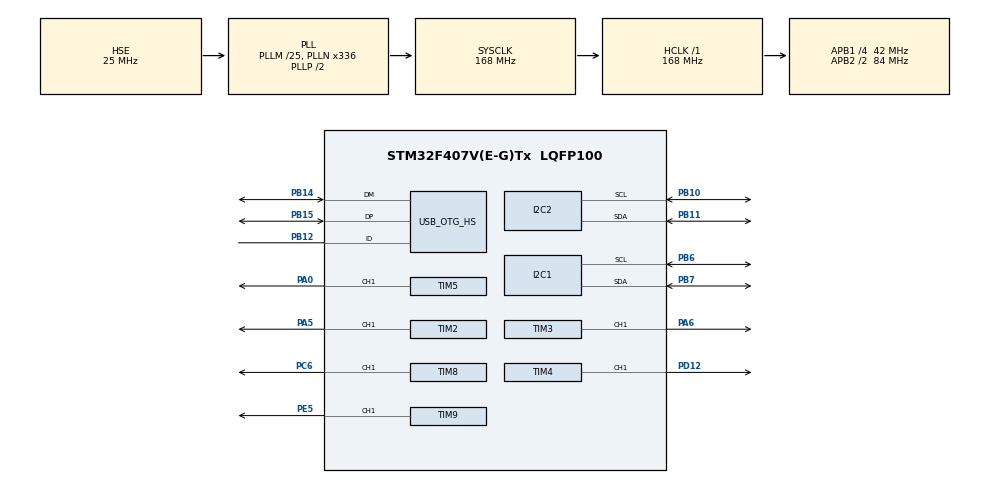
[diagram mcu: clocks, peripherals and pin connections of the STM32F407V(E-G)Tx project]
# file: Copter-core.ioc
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FREERTOS.Tasks01=defaultTask,0,128,StartDefaultTask,Default,NULL
Mcu.Family=STM32F4
Mcu.Name=STM32F407V(E-G)Tx
Mcu.Package=LQFP100
NVIC.PriorityGroup=NVIC_PRIORITYGROUP_4
NVIC.TIM1_UP_TIM10_IRQn=true\:0\:0\:false\:false\:true\:false\:false
NVIC.TimeBase=TIM1_UP_TIM10_IRQn
NVIC.TimeBaseIP=TIM1
PA0-WKUP.Signal=S_TIM5_CH1
PA13.Mode=JTAG_4_pins
PA13.Signal=SYS_JTMS-SWDIO
PA14.Mode=JTAG_4_pins
PA14.Signal=SYS_JTCK-SWCLK
PA15.Mode=JTAG_4_pins
PA15.Signal=SYS_JTDI
PA5.Signal=S_TIM2_CH1_ETR
PA6.Signal=S_TIM3_CH1
PB10.Mode=I2C
PB10.Signal=I2C2_SCL
PB11.Mode=I2C
PB11.Signal=I2C2_SDA
PB12.Mode=OTG/Dual-Role-Device-FS
PB12.Signal=USB_OTG_HS_ID
PB14.Mode=OTG/Dual-Role-Device-FS
PB14.Signal=USB_OTG_HS_DM
PB15.Mode=OTG/Dual-Role-Device-FS
PB15.Signal=USB_OTG_HS_DP
PB3.Mode=JTAG_4_pins
PB3.Signal=SYS_JTDO-SWO
PB6.Mode=I2C
PB6.Signal=I2C1_SCL
PB7.Mode=I2C
PB7.Signal=I2C1_SDA
PC6.Signal=S_TIM8_CH1
PD12.Signal=S_TIM4_CH1
PE5.Signal=S_TIM9_CH1
PH0-OSC_IN.Mode=HSE-External-Oscillator
PH0-OSC_IN.Signal=RCC_OSC_IN
PH1-OSC_OUT.Mode=HSE-External-Oscillator
PH1-OSC_OUT.Signal=RCC_OSC_OUT
ProjectManager.HeapSize=0x200
ProjectManager.StackSize=0x400
ProjectManager.TargetToolchain=TrueSTUDIO
RCC.48MHZClocksFreq_Value=48000000
RCC.AHBFreq_Value=168000000
RCC.APB1CLKDivider=RCC_HCLK_DIV4
RCC.APB1Freq_Value=42000000
RCC.APB1TimFreq_Value=84000000
RCC.APB2CLKDivider=RCC_HCLK_DIV2
RCC.APB2Freq_Value=84000000
RCC.APB2TimFreq_Value=168000000
RCC.CortexFreq_Value=168000000
RCC.HCLKFreq_Value=168000000
RCC.HSE_VALUE=25000000
RCC.HSI_VALUE=16000000
RCC.LSE_VALUE=32768
RCC.PLLM=25
RCC.PLLN=336
RCC.PLLQ=7
RCC.SYSCLKFreq_VALUE=168000000
RCC.SYSCLKSource=RCC_SYSCLKSOURCE_PLLCLK
RCC.VCOOutputFreq_Value=336000000
SH.S_TIM2_CH1_ETR.0=TIM2_CH1,PWM Generation1 CH1
SH.S_TIM3_CH1.0=TIM3_CH1,PWM Generation1 CH1
SH.S_TIM4_CH1.0=TIM4_CH1,PWM Generation1 CH1
SH.S_TIM5_CH1.0=TIM5_CH1,PWM Generation1 CH1
SH.S_TIM8_CH1.0=TIM8_CH1,PWM Generation1 CH1
SH.S_TIM9_CH1.0=TIM9_CH1,PWM Generation1 CH1
TIM2.Channel-PWM\ Generation1\ CH1=TIM_CHANNEL_1
TIM3.Channel-PWM\ Generation1\ CH1=TIM_CHANNEL_1
TIM4.Channel-PWM\ Generation1\ CH1=TIM_CHANNEL_1
TIM5.Channel-PWM\ Generation1\ CH1=TIM_CHANNEL_1
TIM8.Channel-PWM\ Generation1\ CH1=TIM_CHANNEL_1
TIM9.Channel-PWM\ Generation1\ CH1=TIM_CHANNEL_1
VP_FREERTOS_VS_ENABLE.Mode=Enabled
VP_SYS_VS_tim1.Mode=TIM1
board=Copter-core

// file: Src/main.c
/**
  ******************************************************************************
  * File Name          : main.c
  * Description        : Main program body
  ******************************************************************************
  * This notice applies to any and all portions of this file
  * that are not between comment pairs USER CODE BEGIN and
  * USER CODE END. Other portions of this file, whether
  * inserted by the user or by software development tools
  * are owned by their respective copyright owners.
  *
  * Copyright (c) 2018 STMicroelectronics International N.V.
  * All rights reserved.
  *
  * Redistribution and use in source and binary forms, with or without
  * modification, are permitted, provided that the following conditions are met:
  *
  * 1. Redistribution of source code must retain the above copyright notice,
  *    this list of conditions and the following disclaimer.
  * 2. Redistributions in binary form must reproduce the above copyright notice,
  *    this list of conditions and the following disclaimer in the documentation
  *    and/or other materials provided with the distribution.
  * 3. Neither the name of STMicroelectronics nor the names of other
  *    contributors to this software may be used to endorse or promote products
  *    derived from this software without specific written permission.
  * 4. This software, including modifications and/or derivative works of this
  *    software, must execute solely and exclusively on microcontroller or
  *    microprocessor devices manufactured by or for STMicroelectronics.
  * 5. Redistribution and use of this software other than as permitted under
  *    this license is void and will automatically terminate your rights under
  *    this license.
  *
  * THIS SOFTWARE IS PROVIDED BY STMICROELECTRONICS AND CONTRIBUTORS "AS IS"
  * AND ANY EXPRESS, IMPLIED OR STATUTORY WARRANTIES, INCLUDING, BUT NOT
  * LIMITED TO, THE IMPLIED WARRANTIES OF MERCHANTABILITY, FITNESS FOR A
  * PARTICULAR PURPOSE AND NON-INFRINGEMENT OF THIRD PARTY INTELLECTUAL PROPERTY
  * RIGHTS ARE DISCLAIMED TO THE FULLEST EXTENT PERMITTED BY LAW. IN NO EVENT
  * SHALL STMICROELECTRONICS OR CONTRIBUTORS BE LIABLE FOR ANY DIRECT, INDIRECT,
  * INCIDENTAL, SPECIAL, EXEMPLARY, OR CONSEQUENTIAL DAMAGES (INCLUDING, BUT NOT
  * LIMITED TO, PROCUREMENT OF SUBSTITUTE GOODS OR SERVICES; LOSS OF USE, DATA,
  * OR PROFITS; OR BUSINESS INTERRUPTION) HOWEVER CAUSED AND ON ANY THEORY OF
  * LIABILITY, WHETHER IN CONTRACT, STRICT LIABILITY, OR TORT (INCLUDING
  * NEGLIGENCE OR OTHERWISE) ARISING IN ANY WAY OUT OF THE USE OF THIS SOFTWARE,
  * EVEN IF ADVISED OF THE POSSIBILITY OF SUCH DAMAGE.
  *
  ******************************************************************************
  */
#include "main.h"
#include "stm32f4xx_hal.h"
#include "cmsis_os.h"

/* USER CODE BEGIN Includes */
#include "barometer.h"
#include "orientation.h"

/* USER CODE END Includes */

I2C_HandleTypeDef hi2c1;
I2C_HandleTypeDef hi2c2;

TIM_HandleTypeDef htim2;
TIM_HandleTypeDef htim3;
TIM_HandleTypeDef htim4;
TIM_HandleTypeDef htim5;
TIM_HandleTypeDef htim8;
TIM_HandleTypeDef htim9;

osThreadId defaultTaskHandle;

/* USER CODE BEGIN PV */
/* Private variables ---------------------------------------------------------*/

/* Task Priority Definitions */
#define TASK_INIT_PRIO	(configMAX_PRIORITIES - 1)
#define TASK_MAIN_PRIO	(tskIDLE_PRIORITY + 1)

/* Task Stack Definitions */
#define DEFAULT_STACK_SIZE	256

/* USER CODE END PV */

void SystemClock_Config(void);
static void MX_GPIO_Init(void);
static void MX_TIM4_Init(void);
static void MX_TIM3_Init(void);
static void MX_TIM2_Init(void);
static void MX_TIM5_Init(void);
static void MX_TIM8_Init(void);
static void MX_TIM9_Init(void);
static void MX_USB_OTG_HS_USB_Init(void);
static void MX_I2C2_Init(void);
static void MX_I2C1_Init(void);
void StartDefaultTask(void const * argument);

void HAL_TIM_MspPostInit(TIM_HandleTypeDef *htim);

/* USER CODE BEGIN PFP */
/* Private function prototypes -----------------------------------------------*/

/* USER CODE END PFP */

int main(void)
{

  /* MCU Configuration----------------------------------------------------------*/

  /* Reset of all peripherals, Initializes the Flash interface and the Systick. */
  HAL_Init();

  /* Configure the system clock */
  SystemClock_Config();

  /* Initialize all configured peripherals */
  MX_GPIO_Init();
  MX_TIM4_Init();
  MX_TIM3_Init();
  MX_TIM2_Init();
  MX_TIM5_Init();
  MX_TIM8_Init();
  MX_TIM9_Init();
  MX_USB_OTG_HS_USB_Init();
  MX_I2C2_Init();
  MX_I2C1_Init();

  /* Create the thread(s) */
  /* definition and creation of defaultTask */
  osThreadDef(defaultTask, StartDefaultTask, osPriorityNormal, 0, 128);
  defaultTaskHandle = osThreadCreate(osThread(defaultTask), NULL);

  /* USER CODE BEGIN RTOS_THREADS */
  /* add threads, ... */
  xTaskCreate(Task_Orientation, "MAIN_ORIENTATION", DEFAULT_STACK_SIZE, NULL, TASK_MAIN_PRIO, NULL);
  xTaskCreate(Task_Barometer, "MAIN_BAROMETER", DEFAULT_STACK_SIZE, NULL, TASK_MAIN_PRIO, NULL);
  //xTaskCreate(Task_USB, "MAIN_USB", DEFAULT_STACK_SIZE, NULL, TASK_MAIN_PRIO, NULL);
  /* USER CODE END RTOS_THREADS */

  /* Start scheduler */
  osKernelStart();

  /* We should never get here as control is now taken by the scheduler */

  /* Infinite loop */
  while (1)
  {

  }

}

/** System Clock Configuration
*/
void SystemClock_Config(void)
{

  RCC_OscInitTypeDef RCC_OscInitStruct;
  RCC_ClkInitTypeDef RCC_ClkInitStruct;

    /**Configure the main internal regulator output voltage
    */
  __HAL_RCC_PWR_CLK_ENABLE();

  __HAL_PWR_VOLTAGESCALING_CONFIG(PWR_REGULATOR_VOLTAGE_SCALE1);

    /**Initializes the CPU, AHB and APB busses clocks
    */
  RCC_OscInitStruct.OscillatorType = RCC_OSCILLATORTYPE_HSE;
  RCC_OscInitStruct.HSEState = RCC_HSE_ON;
  RCC_OscInitStruct.PLL.PLLState = RCC_PLL_ON;
  RCC_OscInitStruct.PLL.PLLSource = RCC_PLLSOURCE_HSE;
  RCC_OscInitStruct.PLL.PLLM = 25;
  RCC_OscInitStruct.PLL.PLLN = 336;
  RCC_OscInitStruct.PLL.PLLP = RCC_PLLP_DIV2;
  RCC_OscInitStruct.PLL.PLLQ = 7;
  if (HAL_RCC_OscConfig(&RCC_OscInitStruct) != HAL_OK)
  {
    _Error_Handler(__FILE__, __LINE__);
  }

    /**Initializes the CPU, AHB and APB busses clocks
    */
  RCC_ClkInitStruct.ClockType = RCC_CLOCKTYPE_HCLK|RCC_CLOCKTYPE_SYSCLK
                              |RCC_CLOCKTYPE_PCLK1|RCC_CLOCKTYPE_PCLK2;
  RCC_ClkInitStruct.SYSCLKSource = RCC_SYSCLKSOURCE_PLLCLK;
  RCC_ClkInitStruct.AHBCLKDivider = RCC_SYSCLK_DIV1;
  RCC_ClkInitStruct.APB1CLKDivider = RCC_HCLK_DIV4;
  RCC_ClkInitStruct.APB2CLKDivider = RCC_HCLK_DIV2;

  if (HAL_RCC_ClockConfig(&RCC_ClkInitStruct, FLASH_LATENCY_5) != HAL_OK)
  {
    _Error_Handler(__FILE__, __LINE__);
  }

    /**Configure the Systick interrupt time
    */
  HAL_SYSTICK_Config(HAL_RCC_GetHCLKFreq()/1000);

    /**Configure the Systick
    */
  HAL_SYSTICK_CLKSourceConfig(SYSTICK_CLKSOURCE_HCLK);

  /* SysTick_IRQn interrupt configuration */
  HAL_NVIC_SetPriority(SysTick_IRQn, 15, 0);
}

/* I2C1 init function */
static void MX_I2C1_Init(void)
{

  hi2c1.Instance = I2C1;
  hi2c1.Init.ClockSpeed = 100000;
  hi2c1.Init.DutyCycle = I2C_DUTYCYCLE_2;
  hi2c1.Init.OwnAddress1 = 0;
  hi2c1.Init.AddressingMode = I2C_ADDRESSINGMODE_7BIT;
  hi2c1.Init.DualAddressMode = I2C_DUALADDRESS_DISABLE;
  hi2c1.Init.OwnAddress2 = 0;
  hi2c1.Init.GeneralCallMode = I2C_GENERALCALL_DISABLE;
  hi2c1.Init.NoStretchMode = I2C_NOSTRETCH_DISABLE;
  if (HAL_I2C_Init(&hi2c1) != HAL_OK)
  {
    _Error_Handler(__FILE__, __LINE__);
  }

}

/* I2C2 init function */
static void MX_I2C2_Init(void)
{

  hi2c2.Instance = I2C2;
  hi2c2.Init.ClockSpeed = 100000;
  hi2c2.Init.DutyCycle = I2C_DUTYCYCLE_2;
  hi2c2.Init.OwnAddress1 = 0;
  hi2c2.Init.AddressingMode = I2C_ADDRESSINGMODE_7BIT;
  hi2c2.Init.DualAddressMode = I2C_DUALADDRESS_DISABLE;
  hi2c2.Init.OwnAddress2 = 0;
  hi2c2.Init.GeneralCallMode = I2C_GENERALCALL_DISABLE;
  hi2c2.Init.NoStretchMode = I2C_NOSTRETCH_DISABLE;
  if (HAL_I2C_Init(&hi2c2) != HAL_OK)
  {
    _Error_Handler(__FILE__, __LINE__);
  }

}

/* TIM2 init function */
static void MX_TIM2_Init(void)
{

  TIM_MasterConfigTypeDef sMasterConfig;
  TIM_OC_InitTypeDef sConfigOC;

  htim2.Instance = TIM2;
  htim2.Init.Prescaler = 0;
  htim2.Init.CounterMode = TIM_COUNTERMODE_UP;
  htim2.Init.Period = 0;
  htim2.Init.ClockDivision = TIM_CLOCKDIVISION_DIV1;
  if (HAL_TIM_PWM_Init(&htim2) != HAL_OK)
  {
    _Error_Handler(__FILE__, __LINE__);
  }

  sMasterConfig.MasterOutputTrigger = TIM_TRGO_RESET;
  sMasterConfig.MasterSlaveMode = TIM_MASTERSLAVEMODE_DISABLE;
  if (HAL_TIMEx_MasterConfigSynchronization(&htim2, &sMasterConfig) != HAL_OK)
  {
    _Error_Handler(__FILE__, __LINE__);
  }

  sConfigOC.OCMode = TIM_OCMODE_PWM1;
  sConfigOC.Pulse = 0;
  sConfigOC.OCPolarity = TIM_OCPOLARITY_HIGH;
  sConfigOC.OCFastMode = TIM_OCFAST_DISABLE;
  if (HAL_TIM_PWM_ConfigChannel(&htim2, &sConfigOC, TIM_CHANNEL_1) != HAL_OK)
  {
    _Error_Handler(__FILE__, __LINE__);
  }

  HAL_TIM_MspPostInit(&htim2);

}

/* TIM3 init function */
static void MX_TIM3_Init(void)
{

  TIM_MasterConfigTypeDef sMasterConfig;
  TIM_OC_InitTypeDef sConfigOC;

  htim3.Instance = TIM3;
  htim3.Init.Prescaler = 0;
  htim3.Init.CounterMode = TIM_COUNTERMODE_UP;
  htim3.Init.Period = 0;
  htim3.Init.ClockDivision = TIM_CLOCKDIVISION_DIV1;
  if (HAL_TIM_PWM_Init(&htim3) != HAL_OK)
  {
    _Error_Handler(__FILE__, __LINE__);
  }

  sMasterConfig.MasterOutputTrigger = TIM_TRGO_RESET;
  sMasterConfig.MasterSlaveMode = TIM_MASTERSLAVEMODE_DISABLE;
  if (HAL_TIMEx_MasterConfigSynchronization(&htim3, &sMasterConfig) != HAL_OK)
  {
    _Error_Handler(__FILE__, __LINE__);
  }

  sConfigOC.OCMode = TIM_OCMODE_PWM1;
  sConfigOC.Pulse = 0;
  sConfigOC.OCPolarity = TIM_OCPOLARITY_HIGH;
  sConfigOC.OCFastMode = TIM_OCFAST_DISABLE;
  if (HAL_TIM_PWM_ConfigChannel(&htim3, &sConfigOC, TIM_CHANNEL_1) != HAL_OK)
  {
    _Error_Handler(__FILE__, __LINE__);
  }

  HAL_TIM_MspPostInit(&htim3);

}

/* TIM4 init function */
static void MX_TIM4_Init(void)
{

  TIM_MasterConfigTypeDef sMasterConfig;
  TIM_OC_InitTypeDef sConfigOC;

  htim4.Instance = TIM4;
  htim4.Init.Prescaler = 0;
  htim4.Init.CounterMode = TIM_COUNTERMODE_UP;
  htim4.Init.Period = 0;
  htim4.Init.ClockDivision = TIM_CLOCKDIVISION_DIV1;
  if (HAL_TIM_PWM_Init(&htim4) != HAL_OK)
  {
    _Error_Handler(__FILE__, __LINE__);
  }

  sMasterConfig.MasterOutputTrigger = TIM_TRGO_RESET;
  sMasterConfig.MasterSlaveMode = TIM_MASTERSLAVEMODE_DISABLE;
  if (HAL_TIMEx_MasterConfigSynchronization(&htim4, &sMasterConfig) != HAL_OK)
  {
    _Error_Handler(__FILE__, __LINE__);
  }

  sConfigOC.OCMode = TIM_OCMODE_PWM1;
  sConfigOC.Pulse = 0;
  sConfigOC.OCPolarity = TIM_OCPOLARITY_HIGH;
  sConfigOC.OCFastMode = TIM_OCFAST_DISABLE;
  if (HAL_TIM_PWM_ConfigChannel(&htim4, &sConfigOC, TIM_CHANNEL_1) != HAL_OK)
  {
    _Error_Handler(__FILE__, __LINE__);
  }

  HAL_TIM_MspPostInit(&htim4);

}

/* TIM5 init function */
static void MX_TIM5_Init(void)
{

  TIM_MasterConfigTypeDef sMasterConfig;
  TIM_OC_InitTypeDef sConfigOC;

  htim5.Instance = TIM5;
  htim5.Init.Prescaler = 0;
  htim5.Init.CounterMode = TIM_COUNTERMODE_UP;
  htim5.Init.Period = 0;
  htim5.Init.ClockDivision = TIM_CLOCKDIVISION_DIV1;
  if (HAL_TIM_PWM_Init(&htim5) != HAL_OK)
  {
    _Error_Handler(__FILE__, __LINE__);
  }

  sMasterConfig.MasterOutputTrigger = TIM_TRGO_RESET;
  sMasterConfig.MasterSlaveMode = TIM_MASTERSLAVEMODE_DISABLE;
  if (HAL_TIMEx_MasterConfigSynchronization(&htim5, &sMasterConfig) != HAL_OK)
  {
    _Error_Handler(__FILE__, __LINE__);
  }

  sConfigOC.OCMode = TIM_OCMODE_PWM1;
  sConfigOC.Pulse = 0;
  sConfigOC.OCPolarity = TIM_OCPOLARITY_HIGH;
  sConfigOC.OCFastMode = TIM_OCFAST_DISABLE;
  if (HAL_TIM_PWM_ConfigChannel(&htim5, &sConfigOC, TIM_CHANNEL_1) != HAL_OK)
  {
    _Error_Handler(__FILE__, __LINE__);
  }

  HAL_TIM_MspPostInit(&htim5);

}

/* TIM8 init function */
static void MX_TIM8_Init(void)
{

  TIM_MasterConfigTypeDef sMasterConfig;
  TIM_OC_InitTypeDef sConfigOC;
  TIM_BreakDeadTimeConfigTypeDef sBreakDeadTimeConfig;

  htim8.Instance = TIM8;
  htim8.Init.Prescaler = 0;
  htim8.Init.CounterMode = TIM_COUNTERMODE_UP;
  htim8.Init.Period = 0;
  htim8.Init.ClockDivision = TIM_CLOCKDIVISION_DIV1;
  htim8.Init.RepetitionCounter = 0;
  if (HAL_TIM_PWM_Init(&htim8) != HAL_OK)
  {
    _Error_Handler(__FILE__, __LINE__);
  }

  sMasterConfig.MasterOutputTrigger = TIM_TRGO_RESET;
  sMasterConfig.MasterSlaveMode = TIM_MASTERSLAVEMODE_DISABLE;
  if (HAL_TIMEx_MasterConfigSynchronization(&htim8, &sMasterConfig) != HAL_OK)
  {
    _Error_Handler(__FILE__, __LINE__);
  }

  sConfigOC.OCMode = TIM_OCMODE_PWM1;
  sConfigOC.Pulse = 0;
  sConfigOC.OCPolarity = TIM_OCPOLARITY_HIGH;
  sConfigOC.OCNPolarity = TIM_OCNPOLARITY_HIGH;
  sConfigOC.OCFastMode = TIM_OCFAST_DISABLE;
  sConfigOC.OCIdleState = TIM_OCIDLESTATE_RESET;
  sConfigOC.OCNIdleState = TIM_OCNIDLESTATE_RESET;
  if (HAL_TIM_PWM_ConfigChannel(&htim8, &sConfigOC, TIM_CHANNEL_1) != HAL_OK)
  {
    _Error_Handler(__FILE__, __LINE__);
  }

  sBreakDeadTimeConfig.OffStateRunMode = TIM_OSSR_DISABLE;
  sBreakDeadTimeConfig.OffStateIDLEMode = TIM_OSSI_DISABLE;
  sBreakDeadTimeConfig.LockLevel = TIM_LOCKLEVEL_OFF;
  sBreakDeadTimeConfig.DeadTime = 0;
  sBreakDeadTimeConfig.BreakState = TIM_BREAK_DISABLE;
  sBreakDeadTimeConfig.BreakPolarity = TIM_BREAKPOLARITY_HIGH;
  sBreakDeadTimeConfig.AutomaticOutput = TIM_AUTOMATICOUTPUT_DISABLE;
  if (HAL_TIMEx_ConfigBreakDeadTime(&htim8, &sBreakDeadTimeConfig) != HAL_OK)
  {
    _Error_Handler(__FILE__, __LINE__);
  }

  HAL_TIM_MspPostInit(&htim8);

}

/* TIM9 init function */
static void MX_TIM9_Init(void)
{

  TIM_OC_InitTypeDef sConfigOC;

  htim9.Instance = TIM9;
  htim9.Init.Prescaler = 0;
  htim9.Init.CounterMode = TIM_COUNTERMODE_UP;
  htim9.Init.Period = 0;
  htim9.Init.ClockDivision = TIM_CLOCKDIVISION_DIV1;
  if (HAL_TIM_PWM_Init(&htim9) != HAL_OK)
  {
    _Error_Handler(__FILE__, __LINE__);
  }

  sConfigOC.OCMode = TIM_OCMODE_PWM1;
  sConfigOC.Pulse = 0;
  sConfigOC.OCPolarity = TIM_OCPOLARITY_HIGH;
  sConfigOC.OCFastMode = TIM_OCFAST_DISABLE;
  if (HAL_TIM_PWM_ConfigChannel(&htim9, &sConfigOC, TIM_CHANNEL_1) != HAL_OK)
  {
    _Error_Handler(__FILE__, __LINE__);
  }

  HAL_TIM_MspPostInit(&htim9);

}

/* USB_OTG_HS init function */
static void MX_USB_OTG_HS_USB_Init(void)
{

}

/** Configure pins as
        * Analog
        * Input
        * Output
        * EVENT_OUT
        * EXTI
     PB12   ------> USB_OTG_HS_ID
     PB14   ------> USB_OTG_HS_DM
     PB15   ------> USB_OTG_HS_DP
*/
static void MX_GPIO_Init(void)
{

  GPIO_InitTypeDef GPIO_InitStruct;

  /* GPIO Ports Clock Enable */
  __HAL_RCC_GPIOE_CLK_ENABLE();
  __HAL_RCC_GPIOH_CLK_ENABLE();
  __HAL_RCC_GPIOA_CLK_ENABLE();
  __HAL_RCC_GPIOB_CLK_ENABLE();
  __HAL_RCC_GPIOD_CLK_ENABLE();
  __HAL_RCC_GPIOC_CLK_ENABLE();

  /*Configure GPIO pins : PB12 PB14 PB15 */
  GPIO_InitStruct.Pin = GPIO_PIN_12|GPIO_PIN_14|GPIO_PIN_15;
  GPIO_InitStruct.Mode = GPIO_MODE_AF_PP;
  GPIO_InitStruct.Pull = GPIO_NOPULL;
  GPIO_InitStruct.Speed = GPIO_SPEED_FREQ_VERY_HIGH;
  GPIO_InitStruct.Alternate = GPIO_AF12_OTG_HS_FS;
  HAL_GPIO_Init(GPIOB, &GPIO_InitStruct);

}

/* StartDefaultTask function */
void StartDefaultTask(void const * argument)
{

  for(;;)
  {
    osDelay(1);
  }
}

void HAL_TIM_PeriodElapsedCallback(TIM_HandleTypeDef *htim)
{
  if (htim->Instance == TIM1) {
    HAL_IncTick();
  }
}

void _Error_Handler(char * file, int line)
{
  while(1)
  {
  }
}

/************************ (C) COPYRIGHT STMicroelectronics *****END OF FILE****/
